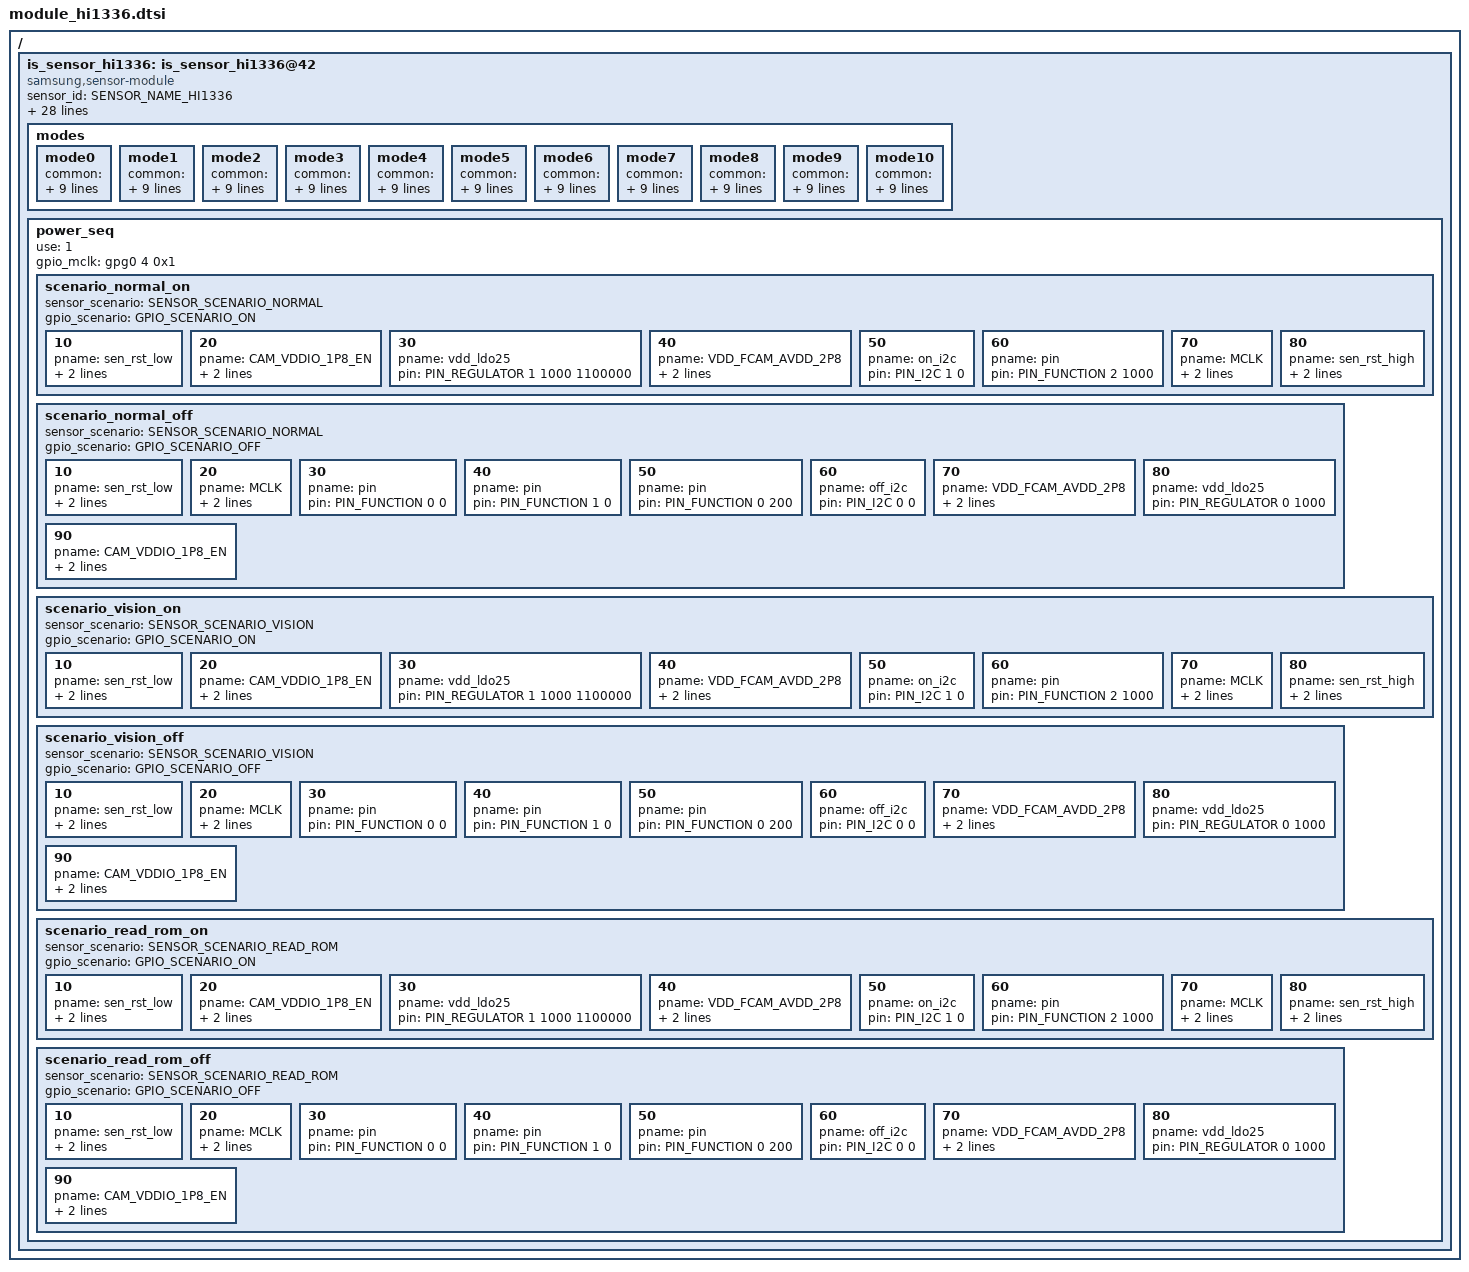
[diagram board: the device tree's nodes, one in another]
/*
 * SAMSUNG EXYNOSxxxx board camera device tree source
 *
 * Copyright (c) 2022 Samsung Electronics Co., Ltd.
 *		http://www.samsung.com
 *
 * This program is free software; you can redistribute it and/or modify
 * it under the terms of the GNU General Public License version 2 as
 * published by the Free Software Foundation.
 */

#include <dt-bindings/camera/exynos_is_dt.h>


/ {
	fragment@camera {
		target-path = "/";
		__overlay__ {
			is_sensor_hi1336: is_sensor_hi1336@42 {
				compatible = "samsung,sensor-module";

				/* common */
				sensor_id = <SENSOR_NAME_HI1336>;
				active_width = <4128>;
				active_height = <3096>;
				margin_left = <0>;
				margin_right = <0>;
				margin_top = <0>;
				margin_bottom = <0>;
				max_framerate = <120>;
				bitwidth = <10>;
				use_retention_mode = <SENSOR_RETENTION_UNSUPPORTED>;
				sensor_maker = "HYNIX";
				sensor_name = "HI1336";
				setfile_name = "setfile_hi1336.bin";
				pinning_setfile;
				preload_setfile;

				status = "okay";

				/* board */
				pinctrl-names = "pin0", "pin1", "pin2", "release";
				pinctrl-0 = <>;
				pinctrl-1 = <&sensor_mclk2_out>;
				pinctrl-2 = <&sensor_mclk2_fn>;
				pinctrl-3 = <>;

				position = <1>; /* Rear:0. Front:1, Tele:2 */
				id = <1>; /* is_sensor id */
				mclk_ch = <2>;
				sensor_i2c_ch = <0>; /* SENSOR_CONTROL_I2C1 */

				/* vendor */
				rom_type = <3>; /* ROM_TYPE_OTPROM */
				rom_id = <1>;
				rom_cal_index = <0>;
				rom_dualcal_id = <0>;
				rom_dualcal_index = <0>;

				/*
				* Reference File : Hi-1336_setting_v4.0.3_SEC26_20221012.xlsx
				*
				*  [ 0 ] 4128 x 3096(4:3)      @30,  MIPI lane: 4, MIPI data rate(Mbps/lane):  1495, Mclk(Mhz): 26
				*  [ 1 ] 4128 x 2324(16:9)     @30,  MIPI lane: 4, MIPI data rate(Mbps/lane):  1456, Mclk(Mhz): 26
				*  [ 2 ] 3088 x 3088(1:1)      @30,  MIPI lane: 4, MIPI data rate(Mbps/lane):  1456, Mclk(Mhz): 26
				*/

				/* sensor modes */
				modes {
						/* common = <width, height, fps, settle, mode, lane, speed, interleave, lrte, pd_mode> */
						/* vcX = <map, hwformat, width, height, hwformat, type, width, height> */

					/* 0 : 2576x1932@30fps 4:3 */
					mode0 {
						common = <4128 3096 30 73 0 CSI_DATA_LANES_4 1495 CSI_MODE_VC_ONLY LRTE_DISABLE PD_NONE EX_NONE>;
						vc0 = </* in */ 0 HW_FORMAT_RAW10 4128 3096	/* out */ HW_FORMAT_RAW10 VC_NOTHING 4128 3096>;
						vc1 = </* in */ 1 HW_FORMAT_UNKNOWN 0 0		/* out */ HW_FORMAT_UNKNOWN VC_NOTHING 0 0>;
						vc2 = </* in */ 2 HW_FORMAT_UNKNOWN 0 0		/* out */ HW_FORMAT_UNKNOWN VC_NOTHING 0 0>;
						vc3 = </* in */ 3 HW_FORMAT_UNKNOWN 0 0		/* out */ HW_FORMAT_UNKNOWN VC_NOTHING 0 0>;
					};
					mode1 {
						common = <4128 2324 30 0 1 CSI_DATA_LANES_4 1456 CSI_MODE_VC_ONLY LRTE_DISABLE PD_NONE EX_NONE>;
						vc0 = </* in */ 0 HW_FORMAT_RAW10 4128 2324	/* out */ HW_FORMAT_RAW10 VC_NOTHING 4128 2324>;
						vc1 = </* in */ 1 HW_FORMAT_UNKNOWN 0 0		/* out */ HW_FORMAT_UNKNOWN VC_NOTHING 0 0>;
						vc2 = </* in */ 2 HW_FORMAT_UNKNOWN 0 0		/* out */ HW_FORMAT_UNKNOWN VC_NOTHING 0 0>;
						vc3 = </* in */ 3 HW_FORMAT_UNKNOWN 0 0		/* out */ HW_FORMAT_UNKNOWN VC_NOTHING 0 0>;
					};
					mode2 {
						common = <4128 1908 30 0 2 CSI_DATA_LANES_4 1456 CSI_MODE_VC_ONLY LRTE_DISABLE PD_NONE EX_NONE>;
						vc0 = </* in */ 0 HW_FORMAT_RAW10 4128 1908	/* out */ HW_FORMAT_RAW10 VC_NOTHING 4128 1908>;
						vc1 = </* in */ 1 HW_FORMAT_UNKNOWN 0 0		/* out */ HW_FORMAT_UNKNOWN VC_NOTHING 0 0>;
						vc2 = </* in */ 2 HW_FORMAT_UNKNOWN 0 0		/* out */ HW_FORMAT_UNKNOWN VC_NOTHING 0 0>;
						vc3 = </* in */ 3 HW_FORMAT_UNKNOWN 0 0		/* out */ HW_FORMAT_UNKNOWN VC_NOTHING 0 0>;
					};
					mode3 {
						common = <3088 3088 30 0 3 CSI_DATA_LANES_4 1456 CSI_MODE_VC_ONLY LRTE_DISABLE PD_NONE EX_NONE>;
						vc0 = </* in */ 0 HW_FORMAT_RAW10 3088 3088	/* out */ HW_FORMAT_RAW10 VC_NOTHING 3088 3088>;
						vc1 = </* in */ 1 HW_FORMAT_UNKNOWN 0 0		/* out */ HW_FORMAT_UNKNOWN VC_NOTHING 0 0>;
						vc2 = </* in */ 2 HW_FORMAT_UNKNOWN 0 0		/* out */ HW_FORMAT_UNKNOWN VC_NOTHING 0 0>;
						vc3 = </* in */ 3 HW_FORMAT_UNKNOWN 0 0		/* out */ HW_FORMAT_UNKNOWN VC_NOTHING 0 0>;
					};
					mode4 {
						common = <3408 2556 30 0 4 CSI_DATA_LANES_4 1456 CSI_MODE_VC_ONLY LRTE_DISABLE PD_NONE EX_NONE>;
						vc0 = </* in */ 0 HW_FORMAT_RAW10 3408 2556	/* out */ HW_FORMAT_RAW10 VC_NOTHING 3408 2556>;
						vc1 = </* in */ 1 HW_FORMAT_UNKNOWN 0 0		/* out */ HW_FORMAT_UNKNOWN VC_NOTHING 0 0>;
						vc2 = </* in */ 2 HW_FORMAT_UNKNOWN 0 0		/* out */ HW_FORMAT_UNKNOWN VC_NOTHING 0 0>;
						vc3 = </* in */ 3 HW_FORMAT_UNKNOWN 0 0		/* out */ HW_FORMAT_UNKNOWN VC_NOTHING 0 0>;
					};
					mode5 {
						common = <1024 768 120 0 5 CSI_DATA_LANES_4 364 CSI_MODE_VC_ONLY LRTE_DISABLE PD_NONE EX_NONE>;
						vc0 = </* in */ 0 HW_FORMAT_RAW10 1024 768	/* out */ HW_FORMAT_RAW10 VC_NOTHING 1024 768>;
						vc1 = </* in */ 1 HW_FORMAT_UNKNOWN 0 0		/* out */ HW_FORMAT_UNKNOWN VC_NOTHING 0 0>;
						vc2 = </* in */ 2 HW_FORMAT_UNKNOWN 0 0		/* out */ HW_FORMAT_UNKNOWN VC_NOTHING 0 0>;
						vc3 = </* in */ 3 HW_FORMAT_UNKNOWN 0 0		/* out */ HW_FORMAT_UNKNOWN VC_NOTHING 0 0>;
					};
					mode6 {
						common = <2064 1548 30 0 6 CSI_DATA_LANES_4 1456 CSI_MODE_VC_ONLY LRTE_DISABLE PD_NONE EX_NONE>;
						vc0 = </* in */ 0 HW_FORMAT_RAW10 2064 1548	/* out */ HW_FORMAT_RAW10 VC_NOTHING 2064 1548>;
						vc1 = </* in */ 1 HW_FORMAT_UNKNOWN 0 0		/* out */ HW_FORMAT_UNKNOWN VC_NOTHING 0 0>;
						vc2 = </* in */ 2 HW_FORMAT_UNKNOWN 0 0		/* out */ HW_FORMAT_UNKNOWN VC_NOTHING 0 0>;
						vc3 = </* in */ 3 HW_FORMAT_UNKNOWN 0 0		/* out */ HW_FORMAT_UNKNOWN VC_NOTHING 0 0>;
					};
					mode7 {
						common = <2064 1160 30 0 7 CSI_DATA_LANES_4 1456 CSI_MODE_VC_ONLY LRTE_DISABLE PD_NONE EX_NONE>;
						vc0 = </* in */ 0 HW_FORMAT_RAW10 2064 1160	/* out */ HW_FORMAT_RAW10 VC_NOTHING 2064 1160>;
						vc1 = </* in */ 1 HW_FORMAT_UNKNOWN 0 0		/* out */ HW_FORMAT_UNKNOWN VC_NOTHING 0 0>;
						vc2 = </* in */ 2 HW_FORMAT_UNKNOWN 0 0		/* out */ HW_FORMAT_UNKNOWN VC_NOTHING 0 0>;
						vc3 = </* in */ 3 HW_FORMAT_UNKNOWN 0 0		/* out */ HW_FORMAT_UNKNOWN VC_NOTHING 0 0>;
					};
					mode8 {
						common = <1696 1272 30 0 8 CSI_DATA_LANES_4 747 CSI_MODE_VC_ONLY LRTE_DISABLE PD_NONE EX_NONE>;
						vc0 = </* in */ 0 HW_FORMAT_RAW10 1696 1272	/* out */ HW_FORMAT_RAW10 VC_NOTHING 1696 1272>;
						vc1 = </* in */ 1 HW_FORMAT_UNKNOWN 0 0		/* out */ HW_FORMAT_UNKNOWN VC_NOTHING 0 0>;
						vc2 = </* in */ 2 HW_FORMAT_UNKNOWN 0 0		/* out */ HW_FORMAT_UNKNOWN VC_NOTHING 0 0>;
						vc3 = </* in */ 3 HW_FORMAT_UNKNOWN 0 0		/* out */ HW_FORMAT_UNKNOWN VC_NOTHING 0 0>;
					};
					mode9 { // FOR SECURE CAMERA FD SCENARIO
						common = <4128 3096 30 0 0 CSI_DATA_LANES_4 1456 CSI_MODE_VC_ONLY LRTE_DISABLE PD_NONE EX_PDSTAT_OFF>;
						vc0 = </* in */ 0 HW_FORMAT_RAW10 4128 3096	/* out */ HW_FORMAT_RAW10 VC_NOTHING 2064 1548>;
						vc1 = </* in */ 1 HW_FORMAT_UNKNOWN 0 0		/* out */ HW_FORMAT_UNKNOWN VC_NOTHING 0 0>;
						vc2 = </* in */ 2 HW_FORMAT_UNKNOWN 0 0		/* out */ HW_FORMAT_UNKNOWN VC_NOTHING 0 0>;
						vc3 = </* in */ 3 HW_FORMAT_UNKNOWN 0 0		/* out */ HW_FORMAT_UNKNOWN VC_NOTHING 0 0>;
					};
					mode10 {
						common = <3712 2556 30 0 9 CSI_DATA_LANES_4 1456 CSI_MODE_VC_ONLY LRTE_DISABLE PD_NONE EX_NONE>;
						vc0 = </* in */ 0 HW_FORMAT_RAW10 3712 2556	/* out */ HW_FORMAT_RAW10 VC_NOTHING 3712 2556>;
						vc1 = </* in */ 1 HW_FORMAT_UNKNOWN 0 0		/* out */ HW_FORMAT_UNKNOWN VC_NOTHING 0 0>;
						vc2 = </* in */ 2 HW_FORMAT_UNKNOWN 0 0		/* out */ HW_FORMAT_UNKNOWN VC_NOTHING 0 0>;
						vc3 = </* in */ 3 HW_FORMAT_UNKNOWN 0 0		/* out */ HW_FORMAT_UNKNOWN VC_NOTHING 0 0>;
					};
				};

				power_seq {
					use = <1>;
					gpio_mclk = <&gpg0 4 0x1>;
					scenario_normal_on {
						sensor_scenario = <SENSOR_SCENARIO_NORMAL>;
						gpio_scenario = <GPIO_SCENARIO_ON>;

						/* A start node number should be over the 10 for reserved number 0~9. */
						/* pname = "name"; pin = <act value delay voltage>; gpio = <gpx# # 0x1>; */
						10 { pname = "sen_rst_low"; pin = <PIN_OUTPUT 0 0>; gpio = <&gpm9 0 0x1>; };
						20 { pname = "CAM_VDDIO_1P8_EN"; pin = <PIN_OUTPUT 1 1000>; gpio = <&gpp0 5 0x1>; };
						30 { pname = "vdd_ldo25"; pin = <PIN_REGULATOR 1 1000 1100000>; };
						40 { pname = "VDD_FCAM_AVDD_2P8"; pin = <PIN_OUTPUT 1 1000>; gpio = <&gpp1 2 0x1>; };
						50 { pname = "on_i2c"; pin = <PIN_I2C 1 0>; };
						60 { pname = "pin"; pin = <PIN_FUNCTION 2 1000>; };
						70 { pname = "MCLK"; pin = <PIN_MCLK 1 1000>; gpio = <&gpg0 4 0x1>; };
						80 { pname = "sen_rst_high"; pin = <PIN_OUTPUT 1 6000>; gpio = <&gpm9 0 0x1>; };
					};

					scenario_normal_off {
						sensor_scenario = <SENSOR_SCENARIO_NORMAL>;
						gpio_scenario = <GPIO_SCENARIO_OFF>;

						/* A start node number should be over the 10 for reserved number 0~9. */
						/* pname = "name"; pin = <act value delay voltage>; gpio = <gpx# # 0x1>; */
						10 { pname = "sen_rst_low"; pin = <PIN_OUTPUT 0 100>; gpio = <&gpm9 0 0x1>; };	/* Timing of rst and mclk was reversed (-29us). Put 100us delay */
						20 { pname = "MCLK"; pin = <PIN_MCLK 0 0>; gpio = <&gpg0 4 0x1>; };
						30 { pname = "pin"; pin = <PIN_FUNCTION 0 0>; };
						40 { pname = "pin"; pin = <PIN_FUNCTION 1 0>; };
						50 { pname = "pin"; pin = <PIN_FUNCTION 0 200>; };
						60 { pname = "off_i2c"; pin = <PIN_I2C 0 0>; };
						70 { pname = "VDD_FCAM_AVDD_2P8"; pin = <PIN_OUTPUT 0 1000>; gpio = <&gpp1 2 0x1>; };
						80 { pname = "vdd_ldo25"; pin = <PIN_REGULATOR 0 1000>; };
						90 { pname = "CAM_VDDIO_1P8_EN"; pin = <PIN_OUTPUT 0 1000>; gpio = <&gpp0 5 0x1>; };
					};

					scenario_vision_on {
						sensor_scenario = <SENSOR_SCENARIO_VISION>;
						gpio_scenario = <GPIO_SCENARIO_ON>;

						/* A start node number should be over the 10 for reserved number 0~9. */
						/* pname = "name"; pin = <act value delay voltage>; gpio = <gpx# # 0x1>; */
						10 { pname = "sen_rst_low"; pin = <PIN_OUTPUT 0 0>; gpio = <&gpm9 0 0x1>; };
						20 { pname = "CAM_VDDIO_1P8_EN"; pin = <PIN_OUTPUT 1 1000>; gpio = <&gpp0 5 0x1>; };
						30 { pname = "vdd_ldo25"; pin = <PIN_REGULATOR 1 1000 1100000>; };
						40 { pname = "VDD_FCAM_AVDD_2P8"; pin = <PIN_OUTPUT 1 1000>; gpio = <&gpp1 2 0x1>; };
						50 { pname = "on_i2c"; pin = <PIN_I2C 1 0>; };
						60 { pname = "pin"; pin = <PIN_FUNCTION 2 1000>; };
						70 { pname = "MCLK"; pin = <PIN_MCLK 1 1000>; gpio = <&gpg0 4 0x1>; };
						80 { pname = "sen_rst_high"; pin = <PIN_OUTPUT 1 6000>; gpio = <&gpm9 0 0x1>; };
					};

					scenario_vision_off {
						sensor_scenario = <SENSOR_SCENARIO_VISION>;
						gpio_scenario = <GPIO_SCENARIO_OFF>;

						/* A start node number should be over the 10 for reserved number 0~9. */
						/* pname = "name"; pin = <act value delay voltage>; gpio = <gpx# # 0x1>; */
						10 { pname = "sen_rst_low"; pin = <PIN_OUTPUT 0 100>; gpio = <&gpm9 0 0x1>; };	/* Timing of rst and mclk was reversed (-29us). Put 100us delay */
						20 { pname = "MCLK"; pin = <PIN_MCLK 0 0>; gpio = <&gpg0 4 0x1>; };
						30 { pname = "pin"; pin = <PIN_FUNCTION 0 0>; };
						40 { pname = "pin"; pin = <PIN_FUNCTION 1 0>; };
						50 { pname = "pin"; pin = <PIN_FUNCTION 0 200>; };
						60 { pname = "off_i2c"; pin = <PIN_I2C 0 0>; };
						70 { pname = "VDD_FCAM_AVDD_2P8"; pin = <PIN_OUTPUT 0 1000>; gpio = <&gpp1 2 0x1>; };
						80 { pname = "vdd_ldo25"; pin = <PIN_REGULATOR 0 1000>; };
						90 { pname = "CAM_VDDIO_1P8_EN"; pin = <PIN_OUTPUT 0 1000>; gpio = <&gpp0 5 0x1>; };
					};

					scenario_read_rom_on {
						sensor_scenario = <SENSOR_SCENARIO_READ_ROM>;
						gpio_scenario = <GPIO_SCENARIO_ON>;

						/* A start node number should be over the 10 for reserved number 0~9. */
						/* pname = "name"; pin = <act value delay voltage>; gpio = <gpx# # 0x1>; */
						10 { pname = "sen_rst_low"; pin = <PIN_OUTPUT 0 0>; gpio = <&gpm9 0 0x1>; };
						20 { pname = "CAM_VDDIO_1P8_EN"; pin = <PIN_OUTPUT 1 1000>; gpio = <&gpp0 5 0x1>; };
						30 { pname = "vdd_ldo25"; pin = <PIN_REGULATOR 1 1000 1100000>; };
						40 { pname = "VDD_FCAM_AVDD_2P8"; pin = <PIN_OUTPUT 1 1000>; gpio = <&gpp1 2 0x1>; };
						50 { pname = "on_i2c"; pin = <PIN_I2C 1 0>; };
						60 { pname = "pin"; pin = <PIN_FUNCTION 2 1000>; };
						70 { pname = "MCLK"; pin = <PIN_MCLK 1 1000>; gpio = <&gpg0 4 0x1>; };
						80 { pname = "sen_rst_high"; pin = <PIN_OUTPUT 1 6000>; gpio = <&gpm9 0 0x1>; };
					};

					scenario_read_rom_off {
						sensor_scenario = <SENSOR_SCENARIO_READ_ROM>;
						gpio_scenario = <GPIO_SCENARIO_OFF>;

						/* A start node number should be over the 10 for reserved number 0~9. */
						/* pname = "name"; pin = <act value delay voltage>; gpio = <gpx# # 0x1>; */
						10 { pname = "sen_rst_low"; pin = <PIN_OUTPUT 0 100>; gpio = <&gpm9 0 0x1>; };	/* Timing of rst and mclk was reversed (-29us). Put 100us delay */
						20 { pname = "MCLK"; pin = <PIN_MCLK 0 0>; gpio = <&gpg0 4 0x1>; };
						30 { pname = "pin"; pin = <PIN_FUNCTION 0 0>; };
						40 { pname = "pin"; pin = <PIN_FUNCTION 1 0>; };
						50 { pname = "pin"; pin = <PIN_FUNCTION 0 200>; };
						60 { pname = "off_i2c"; pin = <PIN_I2C 0 0>; };
						70 { pname = "VDD_FCAM_AVDD_2P8"; pin = <PIN_OUTPUT 0 1000>; gpio = <&gpp1 2 0x1>; };
						80 { pname = "vdd_ldo25"; pin = <PIN_REGULATOR 0 1000>; };
						90 { pname = "CAM_VDDIO_1P8_EN"; pin = <PIN_OUTPUT 0 1000>; gpio = <&gpp0 5 0x1>; };
					};
				};
			};
		}; /* end of __overlay__ */

	}; /* end of fragment */
}; /* end of root */
